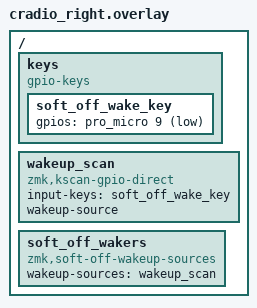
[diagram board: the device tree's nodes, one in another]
/*
 * Only the right inner thumb key (position 32, local kscan column 16,
 * pro_micro pin 9 -- see input-gpios order in cradio.dtsi) can wake this
 * half from soft off. A dedicated "side matrix" kscan watches just that
 * pin and is the only device listed as a soft-off wakeup source, instead
 * of the full kscan0 (which would let any key wake it).
 */

/ {
    keys {
        compatible = "gpio-keys";
        soft_off_wake_key: soft_off_wake_key {
            gpios = <&pro_micro 9 (GPIO_ACTIVE_LOW | GPIO_PULL_UP)>;
        };
    };

    wakeup_scan: wakeup_scan {
        compatible = "zmk,kscan-gpio-direct";
        input-keys = <&soft_off_wake_key>;
        wakeup-source;
    };

    soft_off_wakers {
        compatible = "zmk,soft-off-wakeup-sources";
        wakeup-sources = <&wakeup_scan>;
    };
};
